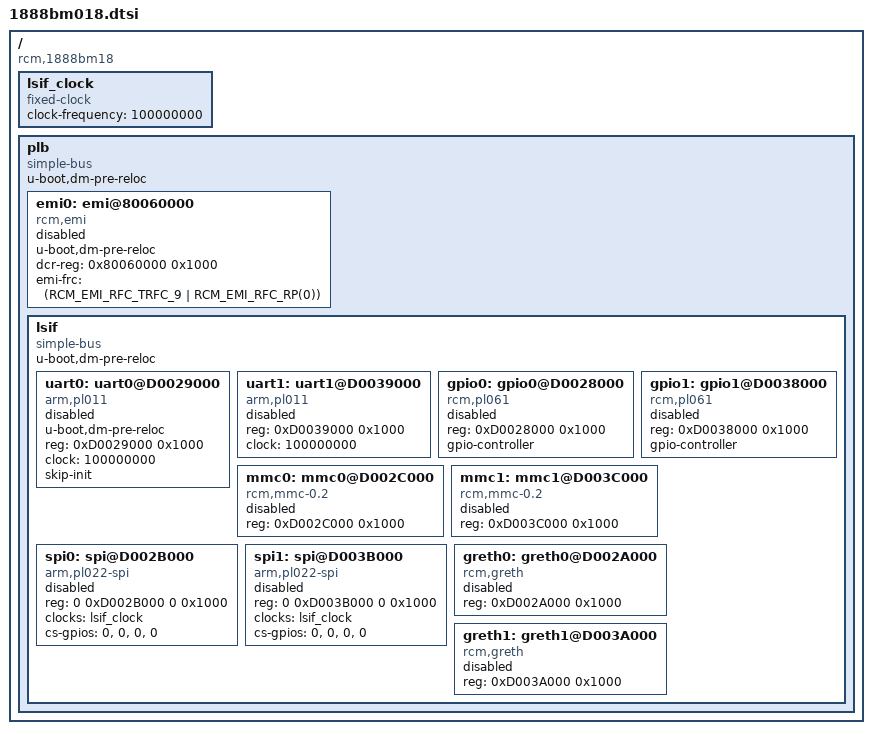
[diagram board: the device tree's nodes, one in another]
/*
 * Device Tree Source for RCM 1888BM018 platform
 *
 * This file is licensed under the terms of the GNU General Public
 * License version 2.  This program is licensed "as is" without
 * any warranty of any kind, whether express or implied.
 */

/dts-v1/;

#include <dt-bindings/memory/rcm-emi.h>

/ {
	compatible = "rcm,1888bm18";
	#address-cells = <1>;
	#size-cells = <1>;

	lsif_clock: lsif_clock {
		#clock-cells = <0>;
		compatible = "fixed-clock";
		clock-frequency = <100000000>;
	};

	plb {
		u-boot,dm-pre-reloc;
		compatible = "simple-bus";
		#address-cells = <1>;
		#size-cells = <1>;

		emi0: emi@80060000 {
			status = "disabled";
			u-boot,dm-pre-reloc;
			compatible = "rcm,emi";
			dcr-reg = <0x80060000 0x1000>;
			emi-frc = <(RCM_EMI_RFC_TRFC_9 | RCM_EMI_RFC_RP(0))>;
		};

		lsif {
			u-boot,dm-pre-reloc;
			compatible = "simple-bus";
			#address-cells = <1>;
			#size-cells = <1>;

			// console
			uart0: uart0@D0029000 {
				status = "disabled";
				u-boot,dm-pre-reloc;
				compatible = "arm,pl011", "arm,primecell";
				reg = <0xD0029000 0x1000>;
				clock = <100000000>;
				skip-init; // the UART speed is configured by RUMBOOT and it depens on the board switches
			};

			uart1: uart1@D0039000 {
				status = "disabled";
				compatible = "arm,pl011", "arm,primecell";
				reg = <0xD0039000 0x1000>;
				clock = <100000000>;
			};

			gpio0: gpio0@D0028000 {
				status = "disabled";
				compatible = "rcm,pl061";
				#address-cells = <1>;
				#size-cells = <0>;
				#gpio-cells = <2>;
				reg = <0xD0028000 0x1000>;
				gpio-controller;
			};

			gpio1: gpio1@D0038000 {
				status = "disabled";
				compatible = "rcm,pl061";
				#address-cells = <1>;
				#size-cells = <0>;
				#gpio-cells = <2>;
				reg = <0xD0038000 0x1000>;
				gpio-controller;
			};

			mmc0: mmc0@D002C000 {
				status = "disabled";
				compatible = "rcm,mmc-0.2";
				reg = <0xD002C000 0x1000>;
			};

			mmc1: mmc1@D003C000 {
				status = "disabled";
				compatible = "rcm,mmc-0.2";
				reg = <0xD003C000 0x1000>;
			};

			spi0: spi@D002B000 {
				status = "disabled";
				compatible = "arm,pl022-spi", "arm,primecell";
				reg = <0 0xD002B000 0 0x1000>;
				#address-cells = <1>;
				#size-cells = <0>;
				clocks = <&lsif_clock>;
				cs-gpios = <0>, <0>, <0>, <0>;
			};

			spi1: spi@D003B000 {
				status = "disabled";
				compatible = "arm,pl022-spi", "arm,primecell";
				reg = <0 0xD003B000 0 0x1000>;
				#address-cells = <1>;
				#size-cells = <0>;
				clocks = <&lsif_clock>;
				cs-gpios = <0>, <0>, <0>, <0>;
			};

			greth0: greth0@D002A000 {
				status = "disabled";
				compatible = "rcm,greth";
				reg = <0xD002A000 0x1000>;
			};

			greth1: greth1@D003A000 {
				status = "disabled";
				compatible = "rcm,greth";
				reg = <0xD003A000 0x1000>;
			};
		};
	};
};

